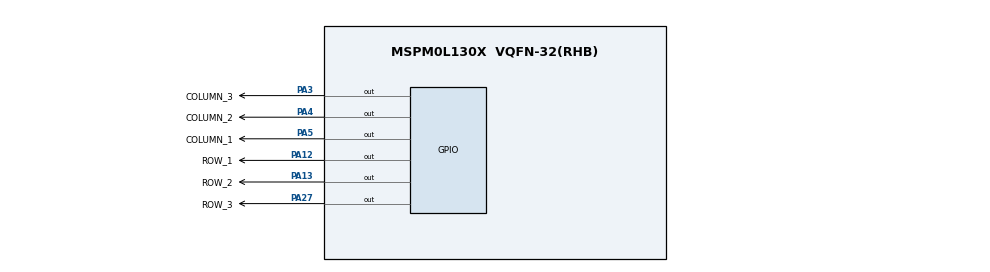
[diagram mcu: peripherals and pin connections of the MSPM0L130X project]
// @cliArgs --device "MSPM0L130X" --package "VQFN-32(RHB)" --part "Default"
// @cliArgs --board /ti/boards/LP_MSPM0L1306 --rtos nortos

/**
 * Import the modules used in this configuration.
 */
const GPIO   = scripting.addModule("/ti/driverlib/GPIO", {}, false);
const GPIO1  = GPIO.addInstance();
const GPIO2  = GPIO.addInstance();
const TIMER  = scripting.addModule("/ti/driverlib/TIMER", {}, false);
const TIMER1 = TIMER.addInstance();

/**
 * Write custom configuration values to the imported modules.
 */
GPIO1.$name                          = "COLUMN";
GPIO1.associatedPins.create(3);
GPIO1.associatedPins[0].$name        = "COLUMN_1";
GPIO1.associatedPins[0].initialValue = "SET";
GPIO1.associatedPins[0].pin.$assign  = "PA5";
GPIO1.associatedPins[1].$name        = "COLUMN_2";
GPIO1.associatedPins[1].initialValue = "SET";
GPIO1.associatedPins[1].pin.$assign  = "PA4";
GPIO1.associatedPins[2].$name        = "COLUMN_3";
GPIO1.associatedPins[2].initialValue = "SET";
GPIO1.associatedPins[2].pin.$assign  = "PA3";

const Board = scripting.addModule("/ti/driverlib/Board", {}, false);

GPIO2.$name                          = "ROW";
GPIO2.associatedPins.create(3);
GPIO2.associatedPins[0].$name        = "ROW_1";
GPIO2.associatedPins[0].initialValue = "SET";
GPIO2.associatedPins[0].pin.$assign  = "PA12";
GPIO2.associatedPins[1].$name        = "ROW_2";
GPIO2.associatedPins[1].initialValue = "SET";
GPIO2.associatedPins[1].pin.$assign  = "PA13";
GPIO2.associatedPins[2].$name        = "ROW_3";
GPIO2.associatedPins[2].initialValue = "SET";
GPIO2.associatedPins[2].pin.$assign  = "PA27";

const SYSCTL = scripting.addModule("/ti/driverlib/SYSCTL", {}, false);

TIMER1.$name              = "LED_STATE";
TIMER1.timerClkDiv        = 8;
TIMER1.timerMode          = "PERIODIC";
TIMER1.timerPeriod        = "5 ms";
TIMER1.timerStartTimer    = true;
TIMER1.interrupts         = ["ZERO"];
TIMER1.peripheral.$assign = "TIMG0";
